# LPC178x_7x register map
File version: 0.9
CPU: CM3 r0p0, little endian, no MPU, no FPU, 3 interrupt priority bits
Registers are 32-bit, read-write, reset 0x0 unless marked. A register's access mark holds for its fields unless they carry their own. Offsets are from the block's base; [hi:lo] are bit positions; {n}, {i} and the like mark numbered series; 'fields as' and 'values as' point back to an identical list.

## RTC — Real Time Clock (RTC)
Base 0x40024000
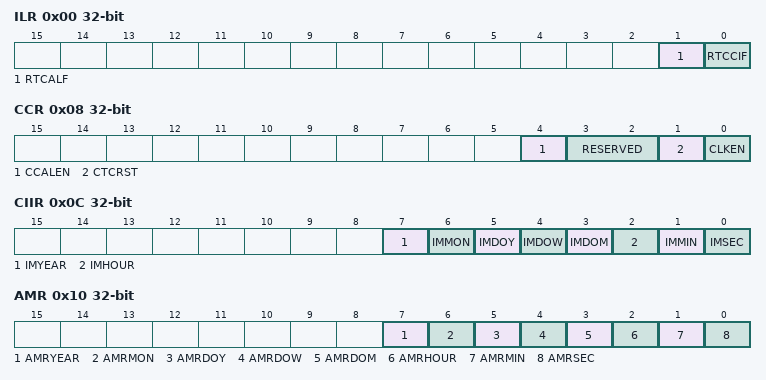
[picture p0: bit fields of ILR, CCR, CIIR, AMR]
0x00 ILR — Interrupt Location Register
  [1] RTCALF — When one, the alarm registers generated an interrupt. Writing a one to this bit location clears the alarm interrupt.
  [0] RTCCIF — When one, the Counter Increment Interrupt block generated an interrupt. Writing a one to this bit location clears the counter increment interrupt.
0x08 CCR reset not defined — Clock Control Register
  [4] CCALEN — Calibration counter enable.
    1=THE_CALIBRATION_COUN (The calibration counter is disabled and reset to zero.); 0=THE_CALIBRATION_COUN (The calibration counter is enabled and counting, using the 1 Hz clock. When the calibration counter is equal to the value of the CALIBRATION register, the counter resets and repeats counting up to the value of the CALIBRATION register. See Section 30.6.4.2 and Section 30.6.5.)
  [3:2] RESERVED — Internal test mode controls. These bits must be 0 for normal RTC operation.
  [1] CTCRST — CTC Reset.
    1=RESET (When one, the elements in the internal oscillator divider are reset, and remain reset until CCR[1] is changed to zero. This is the divider that generates the 1 Hz clock from the 32.768 kHz crystal. The state of the divider is not visible to software.); 0=NO_EFFECT_
  [0] CLKEN — Clock Enable.
    1=THE_TIME_COUNTERS_AR (The time counters are enabled.); 0=THE_TIME_COUNTERS_AR (The time counters are disabled so that they may be initialized.)
0x0C CIIR — Counter Increment Interrupt Register
  [7] IMYEAR — When 1, an increment of the Year value generates an interrupt.
  [6] IMMON — When 1, an increment of the Month value generates an interrupt.
  [5] IMDOY — When 1, an increment of the Day of Year value generates an interrupt.
  [4] IMDOW — When 1, an increment of the Day of Week value generates an interrupt.
  [3] IMDOM — When 1, an increment of the Day of Month value generates an interrupt.
  [2] IMHOUR — When 1, an increment of the Hour value generates an interrupt.
  [1] IMMIN — When 1, an increment of the Minute value generates an interrupt.
  [0] IMSEC — When 1, an increment of the Second value generates an interrupt.
0x10 AMR — Alarm Mask Register
  [7] AMRYEAR — When 1, the Year value is not compared for the alarm.
  [6] AMRMON — When 1, the Month value is not compared for the alarm.
  [5] AMRDOY — When 1, the Day of Year value is not compared for the alarm.
  [4] AMRDOW — When 1, the Day of Week value is not compared for the alarm.
  [3] AMRDOM — When 1, the Day of Month value is not compared for the alarm.
  [2] AMRHOUR — When 1, the Hour value is not compared for the alarm.
  [1] AMRMIN — When 1, the Minutes value is not compared for the alarm.
  [0] AMRSEC — When 1, the Second value is not compared for the alarm.
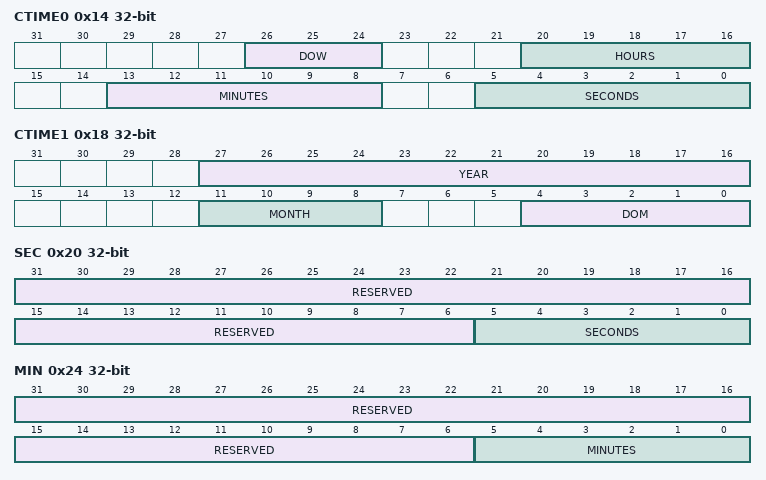
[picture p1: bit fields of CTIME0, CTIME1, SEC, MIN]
0x14 CTIME0 ro reset not defined — Consolidated Time Register 0
  [26:24] DOW — Day of week value in the range of 0 to 6
  [20:16] HOURS — Hours value in the range of 0 to 23
  [13:8] MINUTES — Minutes value in the range of 0 to 59
  [5:0] SECONDS — Seconds value in the range of 0 to 59
0x18 CTIME1 ro reset not defined — Consolidated Time Register 1
  [27:16] YEAR — Year value in the range of 0 to 4095.
  [11:8] MONTH — Month value in the range of 1 to 12.
  [4:0] DOM — Day of month value in the range of 1 to 28, 29, 30, or 31 (depending on the month and whether it is a leap year).
0x1C CTIME2 ro reset not defined — Consolidated Time Register 2
  [11:0] DOY — Day of year value in the range of 1 to 365 (366 for leap years).
0x20 SEC reset not defined — Seconds Counter
  [31:6] RESERVED — Reserved, user software should not write ones to reserved bits. The value read from a reserved bit is not defined.
  [5:0] SECONDS — Seconds value in the range of 0 to 59
0x24 MIN reset not defined — Minutes Register
  [31:6] RESERVED — Reserved, user software should not write ones to reserved bits. The value read from a reserved bit is not defined.
  [5:0] MINUTES — Minutes value in the range of 0 to 59
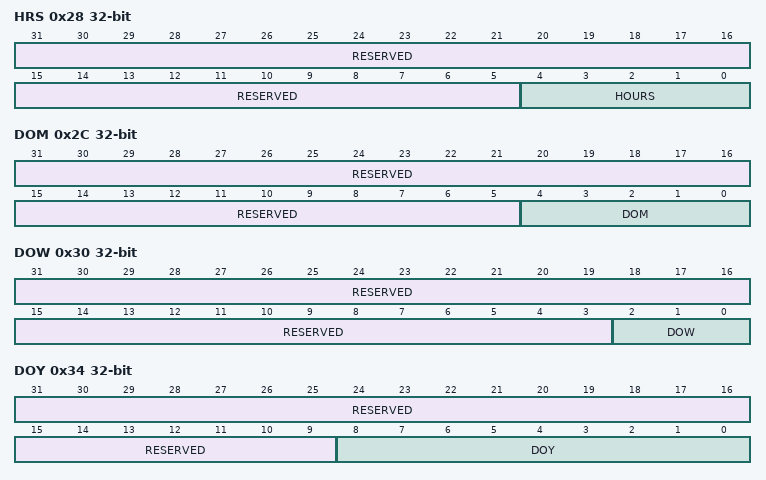
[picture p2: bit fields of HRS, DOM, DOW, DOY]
0x28 HRS reset not defined — Hours Register
  [31:5] RESERVED — Reserved, user software should not write ones to reserved bits. The value read from a reserved bit is not defined.
  [4:0] HOURS — Hours value in the range of 0 to 23
0x2C DOM reset not defined — Day of Month Register
  [31:5] RESERVED — Reserved, user software should not write ones to reserved bits. The value read from a reserved bit is not defined.
  [4:0] DOM — Day of month value in the range of 1 to 28, 29, 30, or 31 (depending on the month and whether it is a leap year).
0x30 DOW reset not defined — Day of Week Register
  [31:3] RESERVED — Reserved, user software should not write ones to reserved bits. The value read from a reserved bit is not defined.
  [2:0] DOW — Day of week value in the range of 0 to 6.
0x34 DOY reset not defined — Day of Year Register
  [31:9] RESERVED — Reserved, user software should not write ones to reserved bits. The value read from a reserved bit is not defined.
  [8:0] DOY — Day of year value in the range of 1 to 365 (366 for leap years).
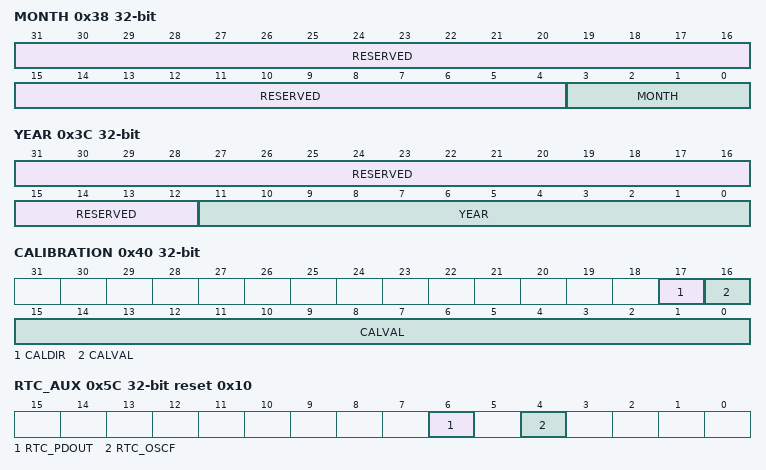
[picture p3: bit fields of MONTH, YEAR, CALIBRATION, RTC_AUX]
0x38 MONTH reset not defined — Months Register
  [31:4] RESERVED — Reserved, user software should not write ones to reserved bits. The value read from a reserved bit is not defined.
  [3:0] MONTH — Month value in the range of 1 to 12.
0x3C YEAR reset not defined — Years Register
  [31:12] RESERVED — Reserved, user software should not write ones to reserved bits. The value read from a reserved bit is not defined.
  [11:0] YEAR — Year value in the range of 0 to 4095.
0x40 CALIBRATION reset not defined — Calibration Value Register
  [17] CALDIR — Calibration direction
    1=BACKWARD_CALIBRATION (Backward calibration. When CALVAL is equal to the calibration counter, the RTC timers will stop incrementing for 1 second.); 0=FORWARD_CALIBRATION_ (Forward calibration. When CALVAL is equal to the calibration counter, the RTC timers will jump by 2 seconds.)
  [16:0] CALVAL — If enabled, the calibration counter counts up to this value. The maximum value is 131, 072 corresponding to about 36.4 hours. Calibration is disabled if CALVAL = 0.
{0x44+4i} GPREG{i} (i=0..4) reset not defined — General Purpose Register 0
  [31:0] GP — General purpose storage.
0x58 RTC_AUXEN — RTC Auxiliary Enable register
  [4] RTC_OSCFEN — Oscillator Fail Detect interrupt enable. When 0: the RTC Oscillator Fail detect interrupt is disabled. When 1: the RTC Oscillator Fail detect interrupt is enabled. See Section 30.6.2.5.
0x5C RTC_AUX reset 0x10 — RTC Auxiliary control register
  [6] RTC_PDOUT — When 0: the RTC_ALARM pin reflects the RTC alarm status. When 1: the RTC_ALARM pin indicates Deep Power-down mode.
  [4] RTC_OSCF — RTC Oscillator Fail detect flag. Read: this bit is set if the RTC oscillator stops, and when RTC power is first turned on. An interrupt will occur when this bit is set, the RTC_OSCFEN bit in RTC_AUXEN is a 1, and the RTC interrupt is enabled in the NVIC. Write: writing a 1 to this bit clears the flag.
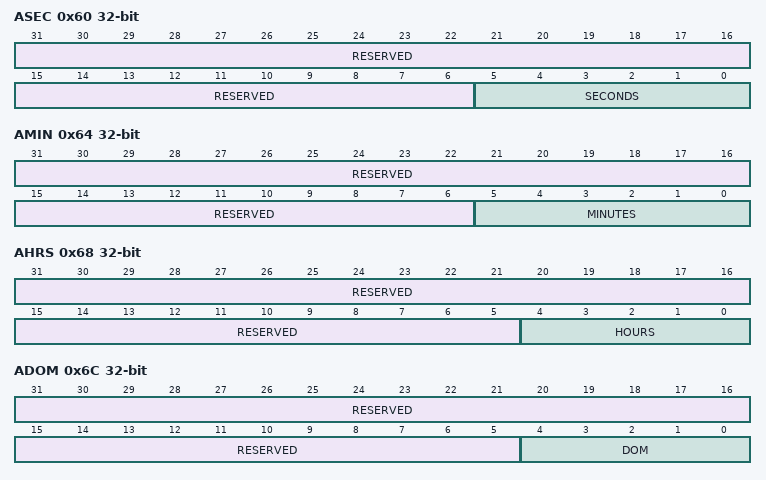
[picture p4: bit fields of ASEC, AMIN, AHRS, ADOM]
0x60 ASEC reset not defined — Alarm value for Seconds
  fields as SEC
0x64 AMIN reset not defined — Alarm value for Minutes
  fields as MIN
0x68 AHRS reset not defined — Alarm value for Hours
  fields as HRS
0x6C ADOM reset not defined — Alarm value for Day of Month
  fields as DOM
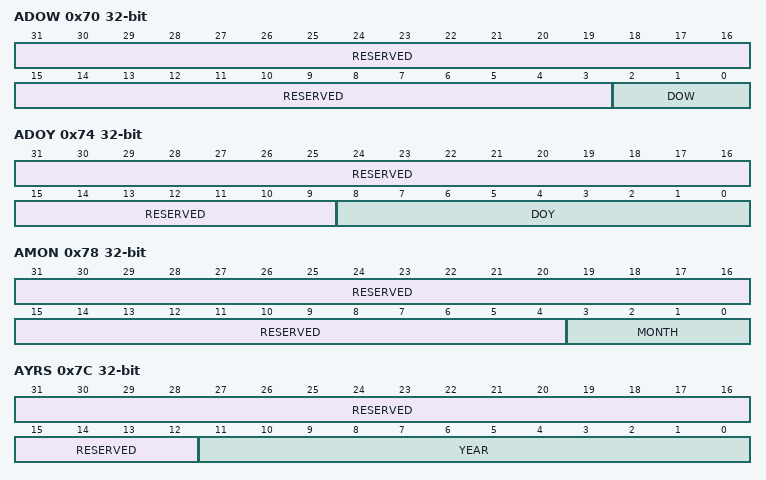
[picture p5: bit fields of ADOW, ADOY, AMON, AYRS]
0x70 ADOW reset not defined — Alarm value for Day of Week
  fields as DOW
0x74 ADOY reset not defined — Alarm value for Day of Year
  fields as DOY
0x78 AMON reset not defined — Alarm value for Months
  fields as MONTH
0x7C AYRS reset not defined — Alarm value for Year
  fields as YEAR
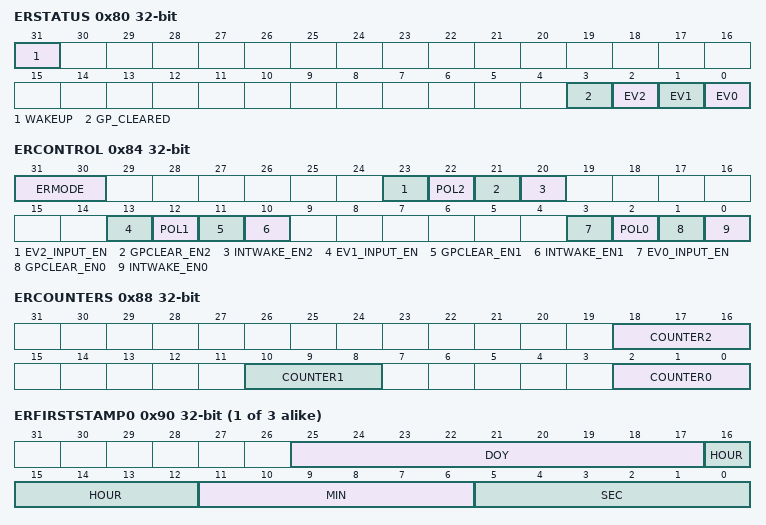
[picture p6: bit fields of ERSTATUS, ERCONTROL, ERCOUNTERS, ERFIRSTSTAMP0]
0x80 ERSTATUS — Event Monitor/Recorder Status register. Contains status flags for event channels and other Event Monitor/Recorder conditions.
  [31] WAKEUP — Interrupt/wakeup request flag (Read-only). This bit is cleared by writing a 1 to it. Writing 0 has no effect.
    0=NO_INTERRUPTWAKEUP_ (No interrupt/wakeup request is pending); 1=INTWAKEUP_PEND (An interrupt/wakeup request is pending.)
  [3] GP_CLEARED — General purpose register asynchronous clear flag. This bit is cleared by writing a 1 to it. Writing 0 has no effect.
    0=NOGPCLR (General purpose registers have not been asynchronous cleared.); 1=GPCLR (General purpose registers have been asynchronous cleared.)
  [2] EV2 — Event flag for channel 2 (RTC_EV2 pin). Set at the end of any second if there has been an event during the preceding second. This bit is cleared by writing a 1 to it. Writing 0 has no effect.
    0=NO_EVENT_CHANGE_ON_C (No event change on channel 2.); 1=AT_LEAST_ONE_EVENT_H (At least one event has occurred on channel 2.)
  [1] EV1 — Event flag for channel 1 (RTC_EV1 pin). Set at the end of any second if there has been an event during the preceding second. This bit is cleared by writing a 1 to it. Writing 0 has no effect.
    0=NO_EVENT_CHANGE_ON_C (No event change on channel 1.); 1=AT_LEAST_ONE_EVENT_H (At least one event has occurred on channel 1.)
  [0] EV0 — Event flag for channel 0 (RTC_EV0 pin). Set at the end of any second if there has been an event during the preceding second. This bit is cleared by writing a 1 to it. Writing 0 has no effect.
    0=NO_EVENT_CHANGE_ON_C (No event change on channel 0.); 1=AT_LEAST_ONE_EVENT_H (At least one event has occurred on channel 0.)
0x84 ERCONTROL — Event Monitor/Recorder Control register. Contains bits that control actions for the event channels as well as for Event Monitor/Recorder setup.
  [31:30] ERMODE — Controls enabling the Event Monitor/Recorder and selecting its operating frequency.[2]
    0=DISABLED (Event Monitor/Recorder clocks are disabled. Operation of the Event Monitor/Recorder is disabled except for asynchronous clearing of GP registers if selected.); 1=ENABLE_EVENT_MONITOR16HZ (Enable Event Monitor/Recorder and select a 16 Hz sample clock for event input edge detection and glitch suppression. Pulses (in either direction) shorter than 62.5 ms to 125 ms will be filtered out.); 2=ENABLE_EVENT_MONITOR64HZ (Enable Event Monitor/Recorder and select a 64 Hz sample clock for event input edge detection and glitch suppression. Pulses (in either direction) shorter than 15.6 ms to 31.2 ms will be filtered out.); 3=ENABLE_EVENT_MONITOR1KHZ (Enable Event Monitor/Recorder and select a 1 kHz sample clock for event input edge detection and glitch suppression. Pulses (in either direction) shorter than 1 ms to 2 ms will be filtered out.)
  [23] EV2_INPUT_EN — Event enable control for channel 2.[1]
    0=DISABLED (Event 2 input is disabled and forced high internally.); 1=ENABLED (Event 2 input is enabled.)
  [22] POL2 — Selects the polarity of an event on input pin RTC_EV2.
    0=NEG (A channel 2 event is defined as a negative edge on RTC_EV2.); 1=POS (A channel 2 event is defined as a positive edge on RTC_EV2.)
  [21] GPCLEAR_EN2 — Enables automatically clearing the RTC general purpose registers when an event occurs on channel 2.
    0=NOGPREG (Channel 2 has no influence on the general purpose registers.); 1=CLRGPREG (An event in channel 2 will clear the general purpose registers asynchronously.)
  [20] INTWAKE_EN2 — Interrupt and wakeup enable for channel 2.
    0=NO_INTERRUPT_OR_WAKE (No interrupt or wakeup will be generated by event channel 2.); 1=WAKEUP (An event in channel 2 will trigger an (RTC) interrupt and a wake-up request.)
  [13] EV1_INPUT_EN — Event enable control for channel 1.[1]
    0=DISABLED (Event 1 input is disabled and forced high internally.); 1=ENABLED (Event 1 input is enabled.)
  [12] POL1 — Selects the polarity of an event on input pin RTC_EV1.
    0=NEG (A channel 1 event is defined as a negative edge on RTC_EV1.); 1=POS (A channel 1 event is defined as a positive edge on RTC_EV1.)
  [11] GPCLEAR_EN1 — Enables automatically clearing the RTC general purpose registers when an event occurs on channel 1.
    0=NOGPREG (Channel 1 has no influence on the general purpose registers.); 1=CLRGPREG (A n event in channel 1 will clear the general purpose registers asynchronously.)
  [10] INTWAKE_EN1 — Interrupt and wakeup enable for channel 1.
    0=NO_INTERRUPT_OR_WAKE (No interrupt or wakeup will be generated by event channel 1.); 1=WAKEUP (An event in channel 1 will trigger an (RTC) interrupt and a wake-up request.)
  [3] EV0_INPUT_EN — Event enable control for channel 0.[1]
    0=DISABLED (Event 0 input is disabled and forced high internally.); 1=ENABLED (Event 0 input is enabled.)
  [2] POL0 — Selects the polarity of an event on input pin RTC_EV0.
    0=NEG (A channel 0 event is defined as a negative edge on RTC_EV0.); 1=POS (A channel 0 event is defined as a positive edge on RTC_EV0.)
  [1] GPCLEAR_EN0 — Enables automatically clearing the RTC general purpose registers when an event occurs on channel 0.
    0=NOGPREG (Channel 0 has no influence on the general purpose registers.); 1=CLRGPREG (An event in channel 0 will clear the general purpose registers asynchronously.)
  [0] INTWAKE_EN0 — Interrupt and wakeup enable for channel 0.
    0=NO_INTERRUPT_OR_WAKE (No interrupt or wakeup will be generated by event channel 0.); 1=AN_EVENT_IN_CHANNEL_ (An event in channel 0 will trigger an (RTC) interrupt and a wake-up request.)
0x88 ERCOUNTERS ro — Event Monitor/Recorder Counters register. Allows reading the counters associated with the event channels.
  [18:16] COUNTER2 — Value of the counter for event 2. See description for COUNTER0.
  [10:8] COUNTER1 — Value of the counter for event 1. See description for COUNTER0.
  [2:0] COUNTER0 — Value of the counter for event 0. If the counter reaches full count (the value 7), it remains there if additional events occur. This counter is cleared when the corresponding EVx bit in the ERSTATUS register is cleared by software.
{0x90+4i} ERFIRSTSTAMP{i} (i=0..2) ro reset not defined — Event Monitor/Recorder First Stamp register for channel 0. Retains the time stamp for the first event on channel 0.
  [25:17] DOY — Day of Year value in the range of 1 to 366.
  [16:12] HOUR — Hours value in the range of 0 to 23.
  [11:6] MIN — Minutes value in the range of 0 to 59.
  [5:0] SEC — Seconds value in the range of 0 to 59.
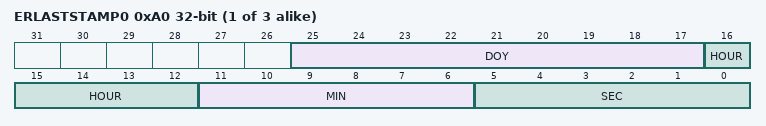
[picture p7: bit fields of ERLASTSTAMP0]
{0xA0+4i} ERLASTSTAMP{i} (i=0..2) ro reset not defined — Event Monitor/Recorder Last Stamp register for channel 0. Retains the time stamp for the last (i.e. most recent) event on channel 0.
  fields as ERFIRSTSTAMP0
